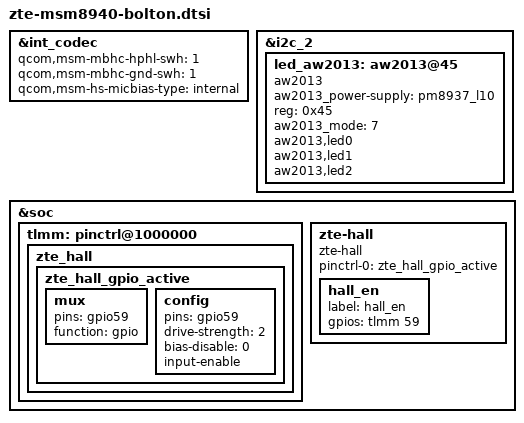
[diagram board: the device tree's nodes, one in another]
/*
 * device tree for zte bolton board
 */

#include "touch-key-backlight-bolton.dtsi"

&int_codec {
	qcom,msm-mbhc-hphl-swh = <1>;
	qcom,msm-mbhc-gnd-swh = <1>;
	qcom,msm-hs-micbias-type = "internal";
};

&i2c_2 {
	led_aw2013:aw2013@45 {
		aw2013_power-supply = <&pm8937_l10>;
		compatible = "aw2013";
		reg = <0x45>;
		status = "ok";
		aw2013_mode = < 7 >;
	};
};

&led_aw2013 {
	aw2013,led0;
	aw2013,led1;
	aw2013,led2;
};

&soc {
	tlmm: pinctrl@1000000 {
		zte_hall: zte_hall {
			zte_hall_gpio_active: zte_hall_gpio_active {
				mux {
					pins = "gpio59";
					function = "gpio";
				};
				config {
					pins = "gpio59";
					drive-strength = <2>; /* 2 mA */
					bias-disable = <0>; /* no pull */
					input-enable; /* input */
				};
			};
		};
	};
};

&soc {
	zte-hall {
		compatible = "zte-hall";
		pinctrl-names = "zte_hall_gpio_active";
		pinctrl-0 = <&zte_hall_gpio_active>;
		hall_en{
			label = "hall_en";
			gpios = <&tlmm 59 0x0>;
		};
	};
};
